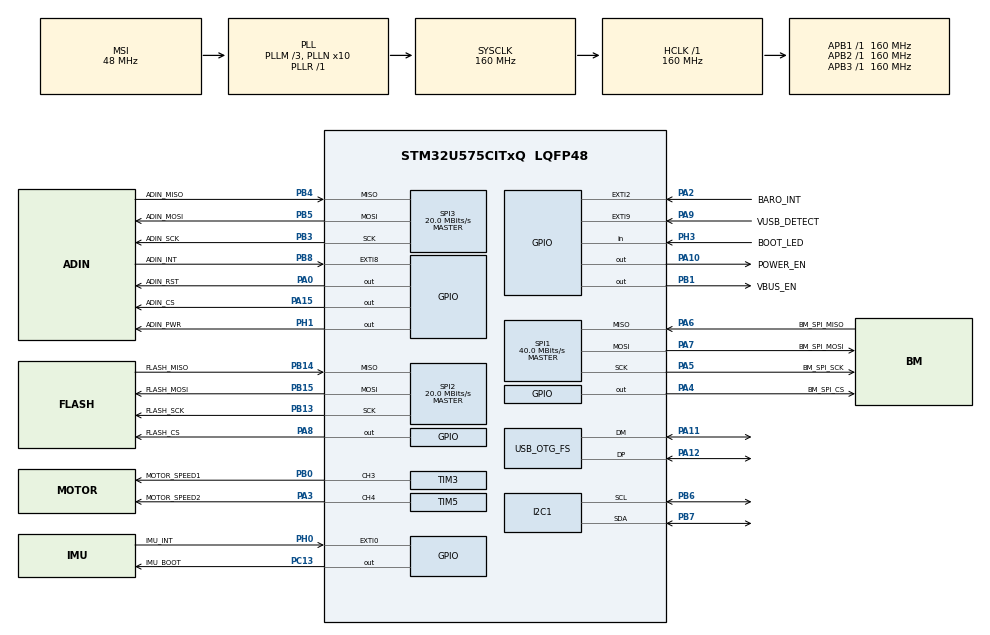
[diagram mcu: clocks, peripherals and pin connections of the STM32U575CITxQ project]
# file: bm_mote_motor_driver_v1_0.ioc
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ADC1.NbrOfConversion=1
ADC1.master=1
CORTEX_M33_NS.userName=CORTEX_M33
GPDMA1.DESTINC_GPDMACH10=DMA_DINC_INCREMENTED
GPDMA1.DESTINC_GPDMACH12=DMA_DINC_INCREMENTED
GPDMA1.DESTINC_GPDMACH15=DMA_DINC_INCREMENTED
GPDMA1.DIRECTION_GPDMACH13=DMA_MEMORY_TO_PERIPH
GPDMA1.DIRECTION_GPDMACH14=DMA_MEMORY_TO_PERIPH
GPDMA1.DIRECTION_GPDMACH15=DMA_PERIPH_TO_MEMORY
GPDMA1.IPHANDLE_GPDMACH10-SIMPLEREQUEST_GPDMACH10=__NULL
GPDMA1.IPHANDLE_GPDMACH11-SIMPLEREQUEST_GPDMACH11=__NULL
GPDMA1.IPHANDLE_GPDMACH12-SIMPLEREQUEST_GPDMACH12=__NULL
GPDMA1.IPHANDLE_GPDMACH13-SIMPLEREQUEST_GPDMACH13=__NULL
GPDMA1.IPHANDLE_GPDMACH14-SIMPLEREQUEST_GPDMACH14=__NULL
GPDMA1.IPHANDLE_GPDMACH15-SIMPLEREQUEST_GPDMACH15=__NULL
GPDMA1.REQUEST_GPDMACH10=GPDMA1_REQUEST_I2C1_RX
GPDMA1.REQUEST_GPDMACH11=GPDMA1_REQUEST_I2C1_TX
GPDMA1.REQUEST_GPDMACH12=GPDMA1_REQUEST_SPI3_RX
GPDMA1.REQUEST_GPDMACH13=GPDMA1_REQUEST_SPI3_TX
GPDMA1.REQUEST_GPDMACH14=GPDMA1_REQUEST_SPI2_TX
GPDMA1.REQUEST_GPDMACH15=GPDMA1_REQUEST_SPI2_RX
GPDMA1.SRCINC_GPDMACH11=DMA_SINC_INCREMENTED
GPDMA1.SRCINC_GPDMACH13=DMA_SINC_INCREMENTED
GPDMA1.SRCINC_GPDMACH14=DMA_SINC_INCREMENTED
I2C1.Timing=0x30909DEC
IWDG.EWI=128
IWDG.Prescaler=IWDG_PRESCALER_32
Mcu.Family=STM32U5
Mcu.Name=STM32U575CITxQ
Mcu.Package=LQFP48
NVIC.EXTI0_IRQn=true\:6\:0\:true\:false\:true\:true\:true\:true
NVIC.EXTI2_IRQn=true\:6\:0\:true\:false\:true\:true\:true\:true
NVIC.EXTI8_IRQn=true\:6\:0\:true\:false\:true\:true\:true\:true
NVIC.EXTI9_IRQn=true\:6\:0\:true\:false\:true\:true\:true\:true
NVIC.GPDMA1_Channel10_IRQn=true\:0\:0\:false\:false\:true\:false\:true\:true
NVIC.GPDMA1_Channel11_IRQn=true\:0\:0\:false\:false\:true\:false\:true\:true
NVIC.GPDMA1_Channel12_IRQn=true\:6\:0\:true\:false\:true\:false\:true\:true
NVIC.GPDMA1_Channel13_IRQn=true\:6\:0\:true\:false\:true\:false\:true\:true
NVIC.GPDMA1_Channel14_IRQn=true\:6\:0\:true\:false\:true\:false\:true\:true
NVIC.GPDMA1_Channel15_IRQn=true\:6\:0\:true\:false\:true\:false\:true\:true
NVIC.I2C1_ER_IRQn=true\:6\:0\:true\:false\:true\:true\:true\:true
NVIC.I2C1_EV_IRQn=true\:6\:0\:true\:false\:true\:true\:true\:true
NVIC.IWDG_IRQn=true\:0\:0\:false\:false\:false\:true\:true\:true
NVIC.PriorityGroup=NVIC_PRIORITYGROUP_4
NVIC.SPI1_IRQn=true\:6\:0\:true\:false\:true\:true\:true\:true
NVIC.SPI2_IRQn=true\:6\:0\:true\:false\:true\:true\:true\:true
NVIC.SPI3_IRQn=true\:6\:0\:true\:false\:true\:true\:true\:true
NVIC.TIM2_IRQn=true\:0\:0\:false\:false\:true\:true\:true\:true
NVIC.TIM8_UP_IRQn=true\:15\:0\:false\:false\:true\:false\:true\:true
NVIC.TimeBase=TIM8_UP_IRQn
NVIC.TimeBaseIP=TIM8
PA0.GPIO_Label=ADIN_RST
PA0.Signal=GPIO_Output
PA10.GPIO_Label=POWER_EN
PA10.Signal=GPIO_Output
PA11.Mode=Device_Only
PA11.Signal=USB_OTG_FS_DM
PA12.Mode=Device_Only
PA12.Signal=USB_OTG_FS_DP
PA13\ (JTMS/SWDIO).Mode=Serial_Wire
PA13\ (JTMS/SWDIO).Signal=DEBUG_JTMS-SWDIO
PA14\ (JTCK/SWCLK).Mode=Serial_Wire
PA14\ (JTCK/SWCLK).Signal=DEBUG_JTCK-SWCLK
PA15\ (JTDI).GPIO_Label=ADIN_CS
PA15\ (JTDI).Signal=GPIO_Output
PA2.GPIO_Label=BARO_INT
PA2.GPIO_ModeDefaultEXTI=GPIO_MODE_IT_FALLING
PA2.Signal=GPXTI2
PA3.GPIO_Label=MOTOR_SPEED2
PA3.Signal=S_TIM5_CH4
PA4.GPIO_Label=BM_SPI_CS
PA4.Signal=GPIO_Output
PA5.GPIO_Label=BM_SPI_SCK
PA5.Mode=Full_Duplex_Master
PA5.Signal=SPI1_SCK
PA6.GPIO_Label=BM_SPI_MISO
PA6.Mode=Full_Duplex_Master
PA6.Signal=SPI1_MISO
PA7.GPIO_Label=BM_SPI_MOSI
PA7.Mode=Full_Duplex_Master
PA7.Signal=SPI1_MOSI
PA8.GPIO_Label=FLASH_CS
PA8.Signal=GPIO_Output
PA9.GPIO_Label=VUSB_DETECT
PA9.GPIO_ModeDefaultEXTI=GPIO_MODE_IT_RISING_FALLING
PA9.Signal=GPXTI9
PB0.GPIO_Label=MOTOR_SPEED1
PB0.Signal=S_TIM3_CH3
PB1.GPIO_Label=VBUS_EN
PB1.Signal=GPIO_Output
PB13.GPIO_Label=FLASH_SCK
PB13.Mode=Full_Duplex_Master
PB13.Signal=SPI2_SCK
PB14.GPIO_Label=FLASH_MISO
PB14.Mode=Full_Duplex_Master
PB14.Signal=SPI2_MISO
PB15.GPIO_Label=FLASH_MOSI
PB15.Mode=Full_Duplex_Master
PB15.Signal=SPI2_MOSI
PB3\ (JTDO/TRACESWO).GPIO_Label=ADIN_SCK
PB3\ (JTDO/TRACESWO).Mode=Full_Duplex_Master
PB3\ (JTDO/TRACESWO).Signal=SPI3_SCK
PB4\ (NJTRST).GPIO_Label=ADIN_MISO
PB4\ (NJTRST).Mode=Full_Duplex_Master
PB4\ (NJTRST).Signal=SPI3_MISO
PB5.GPIO_Label=ADIN_MOSI
PB5.Mode=Full_Duplex_Master
PB5.Signal=SPI3_MOSI
PB6.Mode=I2C
PB6.Signal=I2C1_SCL
PB7.Mode=I2C
PB7.Signal=I2C1_SDA
PB8.GPIO_Label=ADIN_INT
PB8.GPIO_ModeDefaultEXTI=GPIO_MODE_IT_FALLING
PB8.Signal=GPXTI8
PC13.GPIO_Label=IMU_BOOT
PC13.GPIO_PuPd=GPIO_PULLUP
PC13.PinState=GPIO_PIN_SET
PC13.Signal=GPIO_Output
PC14-OSC32_IN\ (PC14).Mode=LSE-External-Oscillator
PC14-OSC32_IN\ (PC14).Signal=RCC_OSC32_IN
PC15-OSC32_OUT\ (PC15).Mode=LSE-External-Oscillator
PC15-OSC32_OUT\ (PC15).Signal=RCC_OSC32_OUT
PH0-OSC_IN\ (PH0).GPIO_Label=IMU_INT
PH0-OSC_IN\ (PH0).GPIO_ModeDefaultEXTI=GPIO_MODE_IT_FALLING
PH0-OSC_IN\ (PH0).Signal=GPXTI0
PH1-OSC_OUT\ (PH1).GPIO_Label=ADIN_PWR
PH1-OSC_OUT\ (PH1).Signal=GPIO_Output
PH3-BOOT0.GPIO_Label=BOOT_LED
PH3-BOOT0.Signal=GPIO_Input
PWR.PowerMode=PWR_SMPS_SUPPLY
ProjectManager.HeapSize=0x200
ProjectManager.StackSize=0x400
ProjectManager.TargetToolchain=STM32CubeIDE
RCC.ADCFreq_Value=16000000
RCC.AHBFreq_Value=160000000
RCC.APB1Freq_Value=160000000
RCC.APB1TimFreq_Value=160000000
RCC.APB2Freq_Value=160000000
RCC.APB2TimFreq_Value=160000000
RCC.APB3Freq_Value=160000000
RCC.CortexFreq_Value=160000000
RCC.DACCLockSelectionVirtual=RCC_DAC1CLKSOURCE_LSI
RCC.EPOD_VALUE=48000000
RCC.HCLKFreq_Value=160000000
RCC.HSE_VALUE=16000000
RCC.HSI48_VALUE=48000000
RCC.HSI_VALUE=16000000
RCC.LPUART1CLockSelectionVirtual=RCC_LPUART1CLKSOURCE_HSI
RCC.LSE_Drive_Capability=RCC_LSEDRIVE_HIGH
RCC.LSIDIV_VALUE=32000
RCC.MSIClockRange=RCC_MSIRANGE_0
RCC.MSI_VALUE=48000000
RCC.PLL1R=1
RCC.PLL2FRACN=0
RCC.PLL3FRACN=0
RCC.PLLFRACN=0
RCC.PLLM=3
RCC.PLLN=10
RCC.RTCClockSelection=RCC_RTCCLKSOURCE_LSE
RCC.SYSCLKFreq_VALUE=160000000
RCC.SYSCLKSource=RCC_SYSCLKSOURCE_PLLCLK
RCC.USBFreq_Value=48000000
RCC.VCOOutputFreq_Value=160000000
SH.S_TIM3_CH3.0=TIM3_CH3,PWM Generation3 CH3
SH.S_TIM5_CH4.0=TIM5_CH4,PWM Generation4 CH4
SPI1.BaudRatePrescaler=SPI_BAUDRATEPRESCALER_4
SPI1.CalculateBaudRate=40.0 MBits/s
SPI1.DataSize=SPI_DATASIZE_8BIT
SPI1.Direction=SPI_DIRECTION_2LINES
SPI1.FirstBit=SPI_FIRSTBIT_MSB
SPI1.Mode=SPI_MODE_MASTER
SPI1.VirtualType=VM_MASTER
SPI2.BaudRatePrescaler=SPI_BAUDRATEPRESCALER_8
SPI2.CalculateBaudRate=20.0 MBits/s
SPI2.DataSize=SPI_DATASIZE_8BIT
SPI2.Direction=SPI_DIRECTION_2LINES
SPI2.Mode=SPI_MODE_MASTER
SPI2.VirtualType=VM_MASTER
SPI3.BaudRatePrescaler=SPI_BAUDRATEPRESCALER_8
SPI3.CalculateBaudRate=20.0 MBits/s
SPI3.Direction=SPI_DIRECTION_2LINES
SPI3.Mode=SPI_MODE_MASTER
SPI3.VirtualType=VM_MASTER
TIM2.AutoReloadPreload=TIM_AUTORELOAD_PRELOAD_DISABLE
TIM2.Prescaler=160-1
TIM3.Channel-PWM\ Generation3\ CH3=TIM_CHANNEL_3
TIM3.PeriodNoDither=1000-1
TIM3.Prescaler=160-1
TIM5.Channel-PWM\ Generation4\ CH4=TIM_CHANNEL_4
TIM5.PeriodNoDither=1000-1
TIM5.Prescaler=160-1
USB_OTG_FS.VirtualMode=Device_Only
VP_ADC1_TempSens_Input.Mode=IN-TempSens
VP_GPDMA1_VS_GPDMACH10.Mode=SIMPLEREQUEST_GPDMACH10
VP_GPDMA1_VS_GPDMACH11.Mode=SIMPLEREQUEST_GPDMACH11
VP_GPDMA1_VS_GPDMACH12.Mode=SIMPLEREQUEST_GPDMACH12
VP_GPDMA1_VS_GPDMACH13.Mode=SIMPLEREQUEST_GPDMACH13
VP_GPDMA1_VS_GPDMACH14.Mode=SIMPLEREQUEST_GPDMACH14
VP_GPDMA1_VS_GPDMACH15.Mode=SIMPLEREQUEST_GPDMACH15
VP_ICACHE_VS_ICACHE.Mode=DirectMappedCache
VP_IWDG_VS_IWDG.Mode=IWDG_Activate
VP_LPBAMQUEUE_VS_QUEUE.Mode=QUEUEMODE
VP_LPBAM_VS_SIG1.Mode=SmartRun
VP_LPBAM_VS_SIG4.Mode=LPDMA1
VP_PWR_VS_DBSignals.Mode=DisableDeadBatterySignals
VP_PWR_VS_LPOM.Mode=PowerOptimisation
VP_PWR_VS_SECSignals.Mode=Security/Privilege
VP_RTC_VS_RTC_Activate.Mode=RTC_Enabled
VP_SYS_VS_tim8.Mode=TIM8
VP_TIM2_VS_ClockSourceINT.Mode=Internal
board=custom

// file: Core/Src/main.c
/* USER CODE BEGIN Header */
/**
  ******************************************************************************
  * @file           : main.c
  * @brief          : Main program body
  ******************************************************************************
  * @attention
  *
  * Copyright (c) 2023 STMicroelectronics.
  * All rights reserved.
  *
  * This software is licensed under terms that can be found in the LICENSE file
  * in the root directory of this software component.
  * If no LICENSE file comes with this software, it is provided AS-IS.
  *
  ******************************************************************************
  */
/* USER CODE END Header */
#include "main.h"
#include "adc.h"
#include "gpdma.h"
#include "i2c.h"
#include "icache.h"
#include "iwdg.h"
#include "rtc.h"
#include "spi.h"
#include "tim.h"
#include "usb_otg.h"
#include "gpio.h"

void SystemClock_Config(void);
static void SystemPower_Config(void);

/* USER CODE BEGIN 0 */
// adding __weak here so we can override main()
// This way we can keep track of all the initialization things we need to port
// over after CubeMX re-generates code
__weak
/* USER CODE END 0 */

int main(void)
{

  /* MCU Configuration--------------------------------------------------------*/

  /* Reset of all peripherals, Initializes the Flash interface and the Systick. */
  HAL_Init();

  /* Configure the System Power */
  SystemPower_Config();

  /* Configure the system clock */
  SystemClock_Config();

  /* Initialize all configured peripherals */
  MX_GPIO_Init();
  MX_GPDMA1_Init();
  MX_USB_OTG_FS_PCD_Init();
  MX_I2C1_Init();
  MX_SPI2_Init();
  MX_SPI3_Init();
  MX_ICACHE_Init();
  MX_IWDG_Init();
  MX_RTC_Init();
  MX_ADC1_Init();
  MX_TIM3_Init();
  MX_SPI1_Init();
  MX_TIM5_Init();
  MX_TIM2_Init();

  /* Infinite loop */
  while (1)
  {

  }
}

void SystemClock_Config(void)
{
  RCC_OscInitTypeDef RCC_OscInitStruct = {0};
  RCC_ClkInitTypeDef RCC_ClkInitStruct = {0};

  /** Configure the main internal regulator output voltage
  */
  if (HAL_PWREx_ControlVoltageScaling(PWR_REGULATOR_VOLTAGE_SCALE1) != HAL_OK)
  {
    Error_Handler();
  }

  /** Configure LSE Drive Capability
  */
  HAL_PWR_EnableBkUpAccess();
  __HAL_RCC_LSEDRIVE_CONFIG(RCC_LSEDRIVE_HIGH);

  /** Initializes the CPU, AHB and APB buses clocks
  */
  RCC_OscInitStruct.OscillatorType = RCC_OSCILLATORTYPE_HSI48|RCC_OSCILLATORTYPE_HSI
                              |RCC_OSCILLATORTYPE_LSI|RCC_OSCILLATORTYPE_LSE
                              |RCC_OSCILLATORTYPE_MSI;
  RCC_OscInitStruct.LSEState = RCC_LSE_ON;
  RCC_OscInitStruct.HSIState = RCC_HSI_ON;
  RCC_OscInitStruct.HSI48State = RCC_HSI48_ON;
  RCC_OscInitStruct.HSICalibrationValue = RCC_HSICALIBRATION_DEFAULT;
  RCC_OscInitStruct.LSIState = RCC_LSI_ON;
  RCC_OscInitStruct.MSIState = RCC_MSI_ON;
  RCC_OscInitStruct.MSICalibrationValue = RCC_MSICALIBRATION_DEFAULT;
  RCC_OscInitStruct.MSIClockRange = RCC_MSIRANGE_0;
  RCC_OscInitStruct.LSIDiv = RCC_LSI_DIV1;
  RCC_OscInitStruct.PLL.PLLState = RCC_PLL_ON;
  RCC_OscInitStruct.PLL.PLLSource = RCC_PLLSOURCE_MSI;
  RCC_OscInitStruct.PLL.PLLMBOOST = RCC_PLLMBOOST_DIV4;
  RCC_OscInitStruct.PLL.PLLM = 3;
  RCC_OscInitStruct.PLL.PLLN = 10;
  RCC_OscInitStruct.PLL.PLLP = 2;
  RCC_OscInitStruct.PLL.PLLQ = 2;
  RCC_OscInitStruct.PLL.PLLR = 1;
  RCC_OscInitStruct.PLL.PLLRGE = RCC_PLLVCIRANGE_1;
  RCC_OscInitStruct.PLL.PLLFRACN = 0;
  if (HAL_RCC_OscConfig(&RCC_OscInitStruct) != HAL_OK)
  {
    Error_Handler();
  }

  /** Initializes the CPU, AHB and APB buses clocks
  */
  RCC_ClkInitStruct.ClockType = RCC_CLOCKTYPE_HCLK|RCC_CLOCKTYPE_SYSCLK
                              |RCC_CLOCKTYPE_PCLK1|RCC_CLOCKTYPE_PCLK2
                              |RCC_CLOCKTYPE_PCLK3;
  RCC_ClkInitStruct.SYSCLKSource = RCC_SYSCLKSOURCE_PLLCLK;
  RCC_ClkInitStruct.AHBCLKDivider = RCC_SYSCLK_DIV1;
  RCC_ClkInitStruct.APB1CLKDivider = RCC_HCLK_DIV1;
  RCC_ClkInitStruct.APB2CLKDivider = RCC_HCLK_DIV1;
  RCC_ClkInitStruct.APB3CLKDivider = RCC_HCLK_DIV1;

  if (HAL_RCC_ClockConfig(&RCC_ClkInitStruct, FLASH_LATENCY_4) != HAL_OK)
  {
    Error_Handler();
  }
}

/**
  * @brief Power Configuration
  * @retval None
  */
static void SystemPower_Config(void)
{

  /*
   * Disable the internal Pull-Up in Dead Battery pins of UCPD peripheral
   */
  HAL_PWREx_DisableUCPDDeadBattery();

  /*
   * Switch to SMPS regulator instead of LDO
   */
  if (HAL_PWREx_ConfigSupply(PWR_SMPS_SUPPLY) != HAL_OK)
  {
    Error_Handler();
  }
}

/* USER CODE BEGIN 4 */
// Since SystemPower_Config is static, we need an accessor function
// to get to it from our other main
void SystemPower_Config_ext(void) {
  SystemPower_Config();
}
extern void tim2_cb(void);
/* USER CODE END 4 */

void HAL_TIM_PeriodElapsedCallback(TIM_HandleTypeDef *htim)
{
  if (htim->Instance == TIM8)
  {
    HAL_IncTick();
  }
  /* USER CODE BEGIN Callback 1 */
  else if (htim->Instance == TIM2) {
    tim2_cb();
  }

  /* USER CODE END Callback 1 */
}

void Error_Handler(void)
{
  __disable_irq();
  while (1)
  {
  }
}
